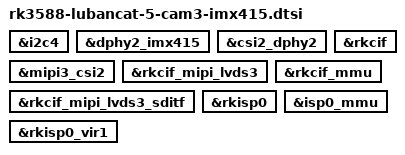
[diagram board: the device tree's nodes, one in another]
&i2c4 {
	status = "okay";
};

&dphy2_imx415 {
	status = "okay";
};

&csi2_dphy2 {
	status = "okay";
};

&mipi3_csi2 {
	status = "okay";
};

&rkcif {
	status = "okay";
};

&rkcif_mipi_lvds3 {
	status = "okay";
};

&rkcif_mipi_lvds3_sditf {
	status = "okay";
};

&rkcif_mmu {
	status = "okay";
};

&rkisp0 {
	status = "okay";
};

&isp0_mmu {
	status = "okay";
};

&rkisp0_vir1 {
	status = "okay";
};

